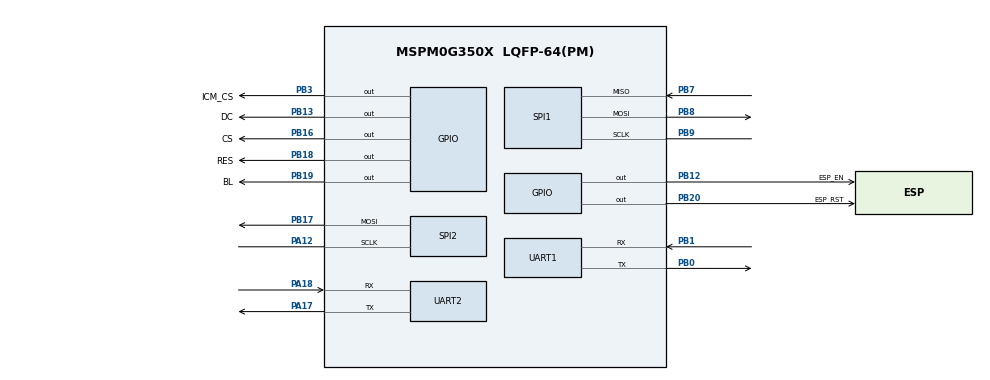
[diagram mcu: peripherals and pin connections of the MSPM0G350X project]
/**
 * @cliArgs --device "MSPM0G350X" --package "LQFP-64(PM)" --part "Default" --product "mspm0_sdk@2.01.00.03"
 * @versions {"tool":"1.19.0+3426"}
 */
scripting.excludeFromBuild("device_linker.cmd");

/**
 * Import the modules used in this configuration.
 */
const GPIO          = scripting.addModule("/ti/driverlib/GPIO", {}, false);
const GPIO1         = GPIO.addInstance();
const GPIO2         = GPIO.addInstance();
const SPI           = scripting.addModule("/ti/driverlib/SPI", {}, false);
const SPI1          = SPI.addInstance();
const SPI2          = SPI.addInstance();
const UART          = scripting.addModule("/ti/driverlib/UART", {}, false);
const UART1         = UART.addInstance();
const UART2         = UART.addInstance();
const ProjectConfig = scripting.addModule("/ti/project_config/ProjectConfig");

/**
 * Write custom configuration values to the imported modules.
 */
GPIO1.$name                          = "TFT";
GPIO1.associatedPins.create(4);
GPIO1.associatedPins[0].$name        = "DC";
GPIO1.associatedPins[0].pin.$assign  = "PB13";
GPIO1.associatedPins[1].$name        = "RES";
GPIO1.associatedPins[1].pin.$assign  = "PB18";
GPIO1.associatedPins[2].$name        = "CS";
GPIO1.associatedPins[2].initialValue = "SET";
GPIO1.associatedPins[2].pin.$assign  = "PB16";
GPIO1.associatedPins[3].$name        = "BL";
GPIO1.associatedPins[3].initialValue = "SET";
GPIO1.associatedPins[3].pin.$assign  = "PB19";

const Board = scripting.addModule("/ti/driverlib/Board", {}, false);

GPIO2.$name                          = "OTHER";
GPIO2.associatedPins.create(3);
GPIO2.associatedPins[0].initialValue = "SET";
GPIO2.associatedPins[0].$name        = "ICM_CS";
GPIO2.associatedPins[0].pin.$assign  = "PB3";
GPIO2.associatedPins[1].$name        = "ESP_EN";
GPIO2.associatedPins[1].initialValue = "SET";
GPIO2.associatedPins[1].pin.$assign  = "PB12";
GPIO2.associatedPins[2].$name        = "ESP_RST";
GPIO2.associatedPins[2].pin.$assign  = "PB20";

SPI1.chipSelect                         = ["1"];
SPI1.$name                              = "ICM_SPI";
SPI1.peripheral.$assign                 = "SPI1";
SPI1.peripheral.sclkPin.$assign         = "PB9";
SPI1.peripheral.mosiPin.$assign         = "PB8";
SPI1.peripheral.misoPin.$assign         = "PB7";
SPI1.sclkPinConfig.$name                = "ti_driverlib_gpio_GPIOPinGeneric0";
SPI1.sclkPinConfig.direction            = scripting.forceWrite("OUTPUT");
SPI1.sclkPinConfig.onlyInternalResistor = scripting.forceWrite(false);
SPI1.sclkPinConfig.passedPeripheralType = scripting.forceWrite("Digital");
SPI1.mosiPinConfig.$name                = "ti_driverlib_gpio_GPIOPinGeneric1";
SPI1.mosiPinConfig.direction            = scripting.forceWrite("OUTPUT");
SPI1.mosiPinConfig.hideOutputInversion  = scripting.forceWrite(false);
SPI1.mosiPinConfig.onlyInternalResistor = scripting.forceWrite(false);
SPI1.mosiPinConfig.passedPeripheralType = scripting.forceWrite("Digital");
SPI1.misoPinConfig.$name                = "ti_driverlib_gpio_GPIOPinGeneric2";
SPI1.misoPinConfig.onlyInternalResistor = scripting.forceWrite(false);
SPI1.misoPinConfig.passedPeripheralType = scripting.forceWrite("Digital");
SPI1.cs1PinConfig.$name                 = "ti_driverlib_gpio_GPIOPinGeneric3";
SPI1.cs1PinConfig.direction             = scripting.forceWrite("OUTPUT");
SPI1.cs1PinConfig.hideOutputInversion   = scripting.forceWrite(false);
SPI1.cs1PinConfig.onlyInternalResistor  = scripting.forceWrite(false);
SPI1.cs1PinConfig.passedPeripheralType  = scripting.forceWrite("Digital");

SPI2.$name                              = "TFT_SPI";
SPI2.peripheral.$assign                 = "SPI0";
SPI2.peripheral.sclkPin.$assign         = "PA12";
SPI2.peripheral.mosiPin.$assign         = "PB17";
SPI2.sclkPinConfig.$name                = "ti_driverlib_gpio_GPIOPinGeneric4";
SPI2.sclkPinConfig.direction            = scripting.forceWrite("OUTPUT");
SPI2.sclkPinConfig.onlyInternalResistor = scripting.forceWrite(false);
SPI2.sclkPinConfig.passedPeripheralType = scripting.forceWrite("Digital");
SPI2.mosiPinConfig.$name                = "ti_driverlib_gpio_GPIOPinGeneric5";
SPI2.mosiPinConfig.direction            = scripting.forceWrite("OUTPUT");
SPI2.mosiPinConfig.hideOutputInversion  = scripting.forceWrite(false);
SPI2.mosiPinConfig.onlyInternalResistor = scripting.forceWrite(false);
SPI2.mosiPinConfig.passedPeripheralType = scripting.forceWrite("Digital");
SPI2.misoPinConfig.$name                = "ti_driverlib_gpio_GPIOPinGeneric6";
SPI2.misoPinConfig.onlyInternalResistor = scripting.forceWrite(false);
SPI2.misoPinConfig.passedPeripheralType = scripting.forceWrite("Digital");
SPI2.cs0PinConfig.$name                 = "ti_driverlib_gpio_GPIOPinGeneric7";
SPI2.cs0PinConfig.direction             = scripting.forceWrite("OUTPUT");
SPI2.cs0PinConfig.hideOutputInversion   = scripting.forceWrite(false);
SPI2.cs0PinConfig.onlyInternalResistor  = scripting.forceWrite(false);
SPI2.cs0PinConfig.passedPeripheralType  = scripting.forceWrite("Digital");

const SYSCTL                 = scripting.addModule("/ti/driverlib/SYSCTL", {}, false);
SYSCTL.forceDefaultClkConfig = true;
SYSCTL.clockTreeEn           = true;

UART1.targetBaudRate                   = 115200;
UART1.$name                            = "ESP01";
UART1.peripheral.rxPin.$assign         = "PB1";
UART1.peripheral.txPin.$assign         = "PB0";
UART1.txPinConfig.$name                = "ti_driverlib_gpio_GPIOPinGeneric8";
UART1.txPinConfig.direction            = scripting.forceWrite("OUTPUT");
UART1.txPinConfig.hideOutputInversion  = scripting.forceWrite(false);
UART1.txPinConfig.onlyInternalResistor = scripting.forceWrite(false);
UART1.txPinConfig.passedPeripheralType = scripting.forceWrite("Digital");
UART1.rxPinConfig.$name                = "ti_driverlib_gpio_GPIOPinGeneric9";
UART1.rxPinConfig.hideOutputInversion  = scripting.forceWrite(false);
UART1.rxPinConfig.onlyInternalResistor = scripting.forceWrite(false);
UART1.rxPinConfig.passedPeripheralType = scripting.forceWrite("Digital");

UART2.targetBaudRate                   = 115200;
UART2.$name                            = "OPENMV";
UART2.peripheral.rxPin.$assign         = "PA18";
UART2.peripheral.txPin.$assign         = "PA17";
UART2.txPinConfig.$name                = "ti_driverlib_gpio_GPIOPinGeneric10";
UART2.txPinConfig.direction            = scripting.forceWrite("OUTPUT");
UART2.txPinConfig.hideOutputInversion  = scripting.forceWrite(false);
UART2.txPinConfig.onlyInternalResistor = scripting.forceWrite(false);
UART2.txPinConfig.passedPeripheralType = scripting.forceWrite("Digital");
UART2.rxPinConfig.$name                = "ti_driverlib_gpio_GPIOPinGeneric11";
UART2.rxPinConfig.hideOutputInversion  = scripting.forceWrite(false);
UART2.rxPinConfig.onlyInternalResistor = scripting.forceWrite(false);
UART2.rxPinConfig.passedPeripheralType = scripting.forceWrite("Digital");

ProjectConfig.deviceSpin = "MSPM0G3507";

/**
 * Pinmux solution for unlocked pins/peripherals. This ensures that minor changes to the automatic solver in a future
 * version of the tool will not impact the pinmux you originally saw.  These lines can be completely deleted in order to
 * re-solve from scratch.
 */
Board.peripheral.$suggestSolution          = "DEBUGSS";
Board.peripheral.swclkPin.$suggestSolution = "PA20";
Board.peripheral.swdioPin.$suggestSolution = "PA19";
SPI1.peripheral.cs1Pin.$suggestSolution    = "PA27";
SPI2.peripheral.misoPin.$suggestSolution   = "PA10";
SPI2.peripheral.cs0Pin.$suggestSolution    = "PA2";
UART1.peripheral.$suggestSolution          = "UART0";
UART2.peripheral.$suggestSolution          = "UART1";
